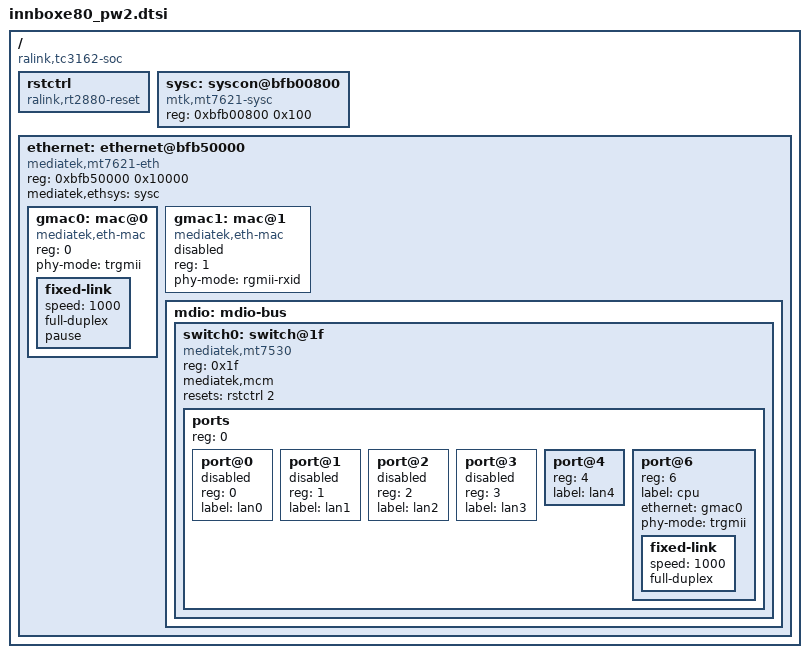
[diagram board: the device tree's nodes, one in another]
/dts-v1/;

/ {
	#address-cells = <1>;
	#size-cells = <1>;
	compatible = "ralink,tc3162-soc";

	rstctrl: rstctrl {
		compatible = "ralink,rt2880-reset";
		#reset-cells = <1>;
	};

	sysc: syscon@bfb00800 {
	      compatible = "mtk,mt7621-sysc", "syscon";
	      reg = <0xbfb00800 0x100>;
	};

	ethernet: ethernet@bfb50000 {
		compatible = "mediatek,mt7621-eth"; 
		reg = <0xbfb50000 0x10000>;

		/* eth->clks is empty for mt7621.
		clocks = <&sysclock>;
		clock-names = "ethif"; */

		#address-cells = <1>;
		#size-cells = <0>;

		/* Not used.
		resets = <&rstctrl 6 &rstctrl 23>;
		reset-names = "fe", "eth"; */

		/* interrupt-parent = <&gic>;
		interrupts = <GIC_SHARED 3 IRQ_TYPE_LEVEL_HIGH>; */

		mediatek,ethsys = <&sysc>;

		gmac0: mac@0 {
			compatible = "mediatek,eth-mac";
			reg = <0>;
			phy-mode = "trgmii";

			fixed-link {
				speed = <1000>;
				full-duplex;
				pause;
			};
		};

		gmac1: mac@1 {
			compatible = "mediatek,eth-mac";
			reg = <1>;
			status = "disable";
			phy-mode = "rgmii-rxid";
		};

		 mdio: mdio-bus {
			#address-cells = <1>;
			#size-cells = <0>;
				
			switch0: switch@1f {
				compatible = "mediatek,mt7530";
				#address-cells = <1>;
				#size-cells = <0>;
				reg = <0x1f>;
				mediatek,mcm;
				resets = <&rstctrl 2>;
				reset-names = "mcm";

				ports {
					#address-cells = <1>;
					#size-cells = <0>;
					reg = <0>;

					port@0 {
						status = "disabled";
						reg = <0>;
						label = "lan0";
					};

					port@1 {
						status = "disabled";
						reg = <1>;
						label = "lan1";
					};

					port@2 {
						status = "disabled"; 
						reg = <2>;
						label = "lan2";
					};

					port@3 {
						status = "disabled";
						reg = <3>;
						label = "lan3";
					};

					port@4 {
						/* status = "disabled"; */
						reg = <4>;
						label = "lan4";
					};

					port@6 {
						reg = <6>;
						label = "cpu";
						ethernet = <&gmac0>;
						phy-mode = "trgmii";

						fixed-link {
							speed = <1000>;
							full-duplex;
						};
					};
				};
			};
		};
	};
};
